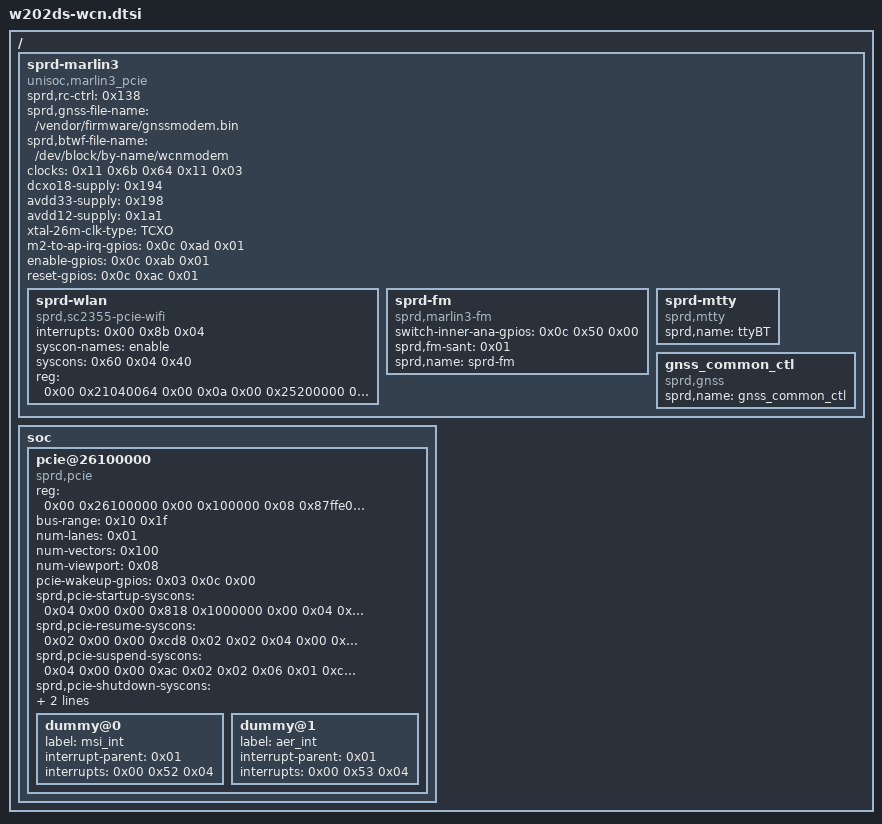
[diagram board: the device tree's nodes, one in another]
// W202DS Server hardware layout; split from the validated imported tree.
/ {
	sprd-marlin3 {
		phandle = <0x258>;
		sprd,rc-ctrl = <0x138>;
		sprd,gnss-file-name = "/vendor/firmware/gnssmodem.bin";
		sprd,btwf-file-name = "/dev/block/by-name/wcnmodem";
		clocks = <0x11 0x6b 0x64 0x11 0x03>;
		clock-names = "clk_32k", "source", "enable";
		dcxo18-supply = <0x194>;
		avdd33-supply = <0x198>;
		avdd12-supply = <0x1a1>;
		xtal-26m-clk-type = "TCXO";
		m2-to-ap-irq-gpios = <0x0c 0xad 0x01>;
		enable-gpios = <0x0c 0xab 0x01>;
		reset-gpios = <0x0c 0xac 0x01>;
		#size-cells = <0x02>;
		#address-cells = <0x02>;
		compatible = "unisoc,marlin3_pcie";
		sprd-wlan {
			interrupt-names = "pam-wifi-irq";
			interrupts = <0x00 0x8b 0x04>;
			syscon-names = "enable";
			syscons = <0x60 0x04 0x40>;
			reg-names = "wifi_ipaqos", "pam_wifi_reg_base_remap";
			reg = <0x00 0x21040064 0x00 0x0a 0x00 0x25200000 0x00 0x3000>;
			compatible = "sprd,sc2355-pcie-wifi";
		};
		sprd-fm {
			switch-inner-ana-gpios = <0x0c 0x50 0x00>;
			sprd,fm-sant = <0x01>;
			sprd,name = "sprd-fm";
			compatible = "sprd,marlin3-fm";
		};
		sprd-mtty {
			sprd,name = "ttyBT";
			compatible = "sprd,mtty";
		};
		gnss_common_ctl {
			sprd,name = "gnss_common_ctl";
			compatible = "sprd,gnss";
		};
	};
	soc {
		pcie@26100000 {
			compatible = "sprd,pcie", "snps,dw-pcie";
			reg = <0x00 0x26100000 0x00 0x100000 0x08 0x87ffe000 0x00 0x100000>;
			reg-names = "dbi", "config";
			#address-cells = <0x03>;
			#size-cells = <0x02>;
			device_type = "pci";
			ranges = <0x1000000 0x00 0x00 0x08 0x87fee000 0x00 0x10000 0x3000000 0x00 0x10000000 0x08 0x80000000 0x00 0x7fee000>;
			bus-range = <0x10 0x1f>;
			num-lanes = <0x01>;
			num-vectors = <0x100>;
			num-viewport = <0x08>;
			pcie-wakeup-gpios = <0x03 0x0c 0x00>;
			status = "okay";
			sprd,pcie-startup-syscons = <0x04 0x00 0x00 0x818 0x1000000 0x00 0x04 0x00 0x00 0xa54 0x40 0x00 0x04 0x00 0x00 0x3e8 0x2000000 0x00 0x04 0x02 0x00 0x548 0x1f000000 0x00 0x04 0x00 0xc8 0xa54 0x01 0x01 0x02 0x00 0x00 0xcd8 0x02 0x02 0x04 0x00 0x7d0 0xac 0x02 0x00>;
			sprd,pcie-resume-syscons = <0x02 0x00 0x00 0xcd8 0x02 0x02 0x04 0x00 0x00 0x3e8 0x2000000 0x00 0x04 0x02 0x00 0x548 0x1f000000 0x00 0x04 0x00 0xc8 0xa54 0x01 0x01 0x05 0x00 0xc8 0x04 0x80 0x80 0x06 0x01 0xc8 0x00 0x10 0x00 0x02 0x02 0x00 0xb34 0x2000 0x00 0x04 0x00 0x7d0 0xac 0x02 0x00>;
			sprd,pcie-suspend-syscons = <0x04 0x00 0x00 0xac 0x02 0x02 0x06 0x01 0xc8 0x00 0x10 0x10 0x02 0x02 0x00 0xb34 0x2000 0x2000 0x05 0x00 0xc8 0x04 0x80 0x00 0x02 0x00 0x00 0xcd8 0x02 0x00 0x04 0x00 0x00 0xa54 0x01 0x00 0x04 0x00 0x00 0x3e8 0x2000000 0x2000000>;
			sprd,pcie-shutdown-syscons = <0x04 0x00 0x00 0xac 0x02 0x02 0x06 0x01 0xc8 0x00 0x10 0x10 0x02 0x02 0x00 0xb34 0x2000 0x2000 0x05 0x00 0xc8 0x04 0x80 0x00 0x02 0x00 0x00 0xcd8 0x02 0x00 0x04 0x00 0x00 0xa54 0x01 0x00 0x04 0x00 0x00 0x3e8 0x2000000 0x2000000>;
			ep-poweron-late;
			phandle = <0x138>;
			dummy@0 {
				label = "msi_int";
				interrupt-parent = <0x01>;
				#interrupt-cells = <0x03>;
				interrupts = <0x00 0x52 0x04>;
			};
			dummy@1 {
				label = "aer_int";
				interrupt-parent = <0x01>;
				#interrupt-cells = <0x03>;
				interrupts = <0x00 0x53 0x04>;
			};
		};
	};
	__symbols__ {
		sprd_marlin3 = "/sprd-marlin3";
		pcie1 = "/soc/pcie@26100000";
	};
};
